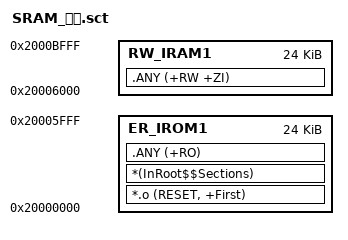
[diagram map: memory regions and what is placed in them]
;本文件用于备份sct文件的配置，要使用时把本文件名改为“SRAM_调试.sct”
;然后复制到Output目录即可。
; *************************************************************
; *** Scatter-Loading Description File generated by uVision ***
; *************************************************************

LR_IROM1 0x20000000  0x00006000  {    ; load region size_region
  ER_IROM1 0x20000000  0x00006000  {  ; load address = execution address
   *.o (RESET, +First)
   *(InRoot$$Sections)
   .ANY (+RO)
  }
  RW_IRAM1 0x20006000 0x00006000  {  ; RW data
   .ANY (+RW +ZI)
  }
}


